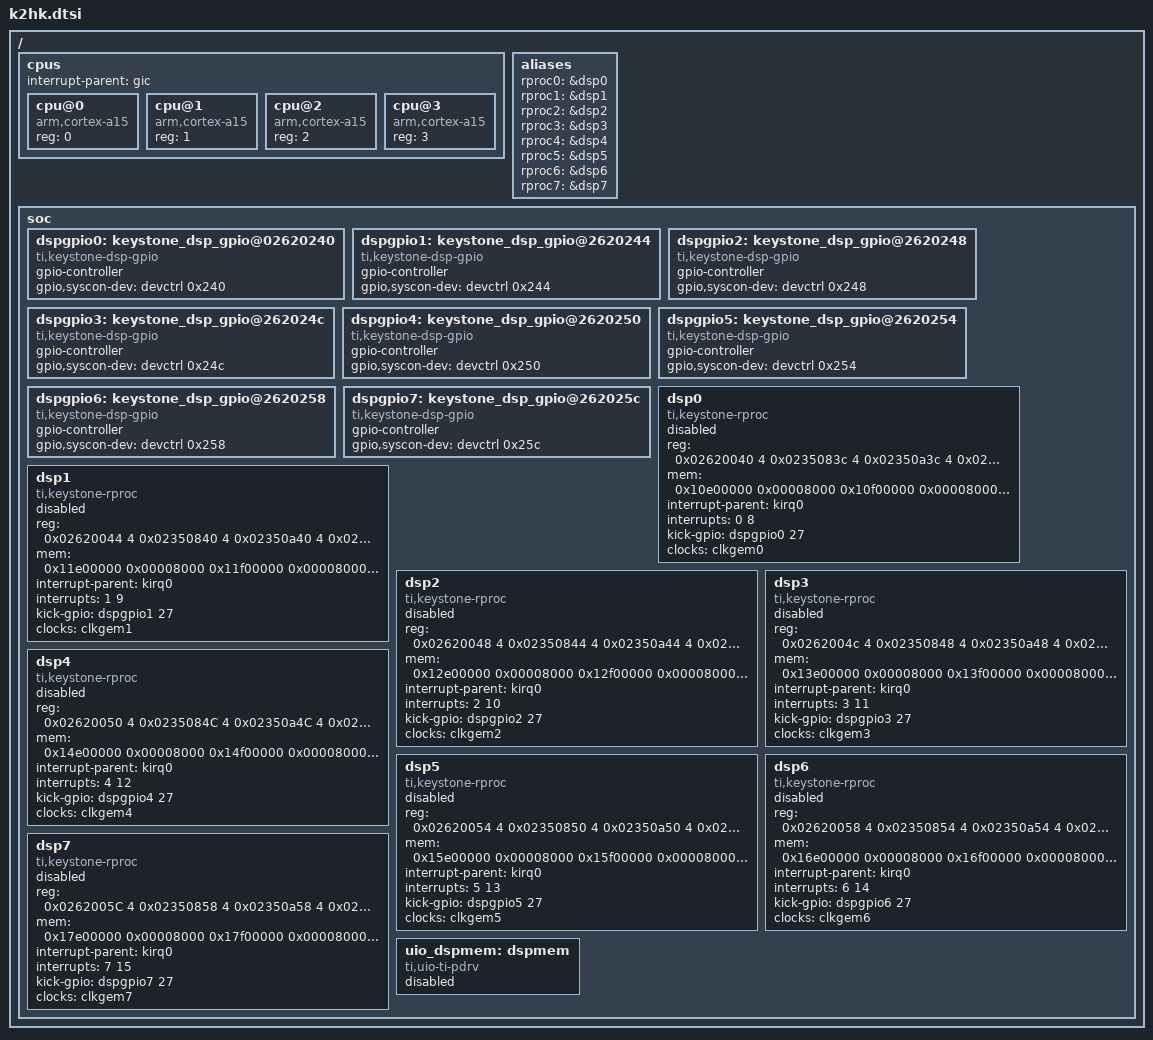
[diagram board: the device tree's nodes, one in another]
/*
 * Copyright 2013-2014 Texas Instruments, Inc.
 *
 * Keystone 2 Kepler/Hawking soc specific device tree
 *
 * This program is free software; you can redistribute it and/or modify
 * it under the terms of the GNU General Public License version 2 as
 * published by the Free Software Foundation.
 */

/ {
	cpus {
		#address-cells = <1>;
		#size-cells = <0>;

		interrupt-parent = <&gic>;

		cpu@0 {
			compatible = "arm,cortex-a15";
			device_type = "cpu";
			reg = <0>;
		};

		cpu@1 {
			compatible = "arm,cortex-a15";
			device_type = "cpu";
			reg = <1>;
		};

		cpu@2 {
			compatible = "arm,cortex-a15";
			device_type = "cpu";
			reg = <2>;
		};

		cpu@3 {
			compatible = "arm,cortex-a15";
			device_type = "cpu";
			reg = <3>;
		};
	};
	aliases {
		rproc0 = &dsp0;
		rproc1 = &dsp1;
		rproc2 = &dsp2;
		rproc3 = &dsp3;
		rproc4 = &dsp4;
		rproc5 = &dsp5;
		rproc6 = &dsp6;
		rproc7 = &dsp7;
	};
	soc {
		/include/ "k2hk-clocks.dtsi"

		dspgpio0: keystone_dsp_gpio@02620240 {
			compatible = "ti,keystone-dsp-gpio";
			gpio-controller;
			#gpio-cells = <2>;
			gpio,syscon-dev = <&devctrl 0x240>;
		};

		dspgpio1: keystone_dsp_gpio@2620244 {
			compatible = "ti,keystone-dsp-gpio";
			gpio-controller;
			#gpio-cells = <2>;
			gpio,syscon-dev = <&devctrl 0x244>;
		};

		dspgpio2: keystone_dsp_gpio@2620248 {
			compatible = "ti,keystone-dsp-gpio";
			gpio-controller;
			#gpio-cells = <2>;
			gpio,syscon-dev = <&devctrl 0x248>;
		};

		dspgpio3: keystone_dsp_gpio@262024c {
			compatible = "ti,keystone-dsp-gpio";
			gpio-controller;
			#gpio-cells = <2>;
			gpio,syscon-dev = <&devctrl 0x24c>;
		};

		dspgpio4: keystone_dsp_gpio@2620250 {
			compatible = "ti,keystone-dsp-gpio";
			gpio-controller;
			#gpio-cells = <2>;
			gpio,syscon-dev = <&devctrl 0x250>;
		};

		dspgpio5: keystone_dsp_gpio@2620254 {
			compatible = "ti,keystone-dsp-gpio";
			gpio-controller;
			#gpio-cells = <2>;
			gpio,syscon-dev = <&devctrl 0x254>;
		};

		dspgpio6: keystone_dsp_gpio@2620258 {
			compatible = "ti,keystone-dsp-gpio";
			gpio-controller;
			#gpio-cells = <2>;
			gpio,syscon-dev = <&devctrl 0x258>;
		};

		dspgpio7: keystone_dsp_gpio@262025c {
			compatible = "ti,keystone-dsp-gpio";
			gpio-controller;
			#gpio-cells = <2>;
			gpio,syscon-dev = <&devctrl 0x25c>;
		};
		dsp0: dsp0 {
			compatible = "ti,keystone-rproc";
			reg = <0x02620040 4
			       0x0235083c 4
			       0x02350a3c 4
			       0x02620240 4>;
			reg-names = "boot-address", "psc-mdstat", "psc-mdctl",
				"ipcgr";
			mem = <0x10e00000 0x00008000
			       0x10f00000 0x00008000
			       0x10800000 0x00100000>;
			interrupt-parent = <&kirq0>;
			interrupts = <0 8>;
			kick-gpio = <&dspgpio0 27 0>;
			clocks = <&clkgem0>;
			status = "disabled";
		};

		dsp1: dsp1 {
			compatible = "ti,keystone-rproc";
			reg = <0x02620044 4
			       0x02350840 4
			       0x02350a40 4
			       0x02620244 4>;
			reg-names = "boot-address", "psc-mdstat", "psc-mdctl",
				"ipcgr";
			mem = <0x11e00000 0x00008000
			       0x11f00000 0x00008000
			       0x11800000 0x00100000>;
			interrupt-parent = <&kirq0>;
			interrupts = <1 9>;
			kick-gpio = <&dspgpio1 27 0>;
			clocks = <&clkgem1>;
			status = "disabled";
		};

		dsp2: dsp2 {
			compatible = "ti,keystone-rproc";
			reg = <0x02620048 4
			       0x02350844 4
			       0x02350a44 4
			       0x02620248 4>;
			reg-names = "boot-address", "psc-mdstat", "psc-mdctl",
				"ipcgr";
			mem = <0x12e00000 0x00008000
			       0x12f00000 0x00008000
			       0x12800000 0x00100000>;
			interrupt-parent = <&kirq0>;
			interrupts = <2 10>;
			kick-gpio = <&dspgpio2 27 0>;
			clocks = <&clkgem2>;
			status = "disabled";
		};

		dsp3: dsp3 {
			compatible = "ti,keystone-rproc";
			reg = <0x0262004c 4
			       0x02350848 4
			       0x02350a48 4
			       0x0262024c 4>;
			reg-names = "boot-address", "psc-mdstat", "psc-mdctl",
				"ipcgr";
			mem = <0x13e00000 0x00008000
			       0x13f00000 0x00008000
			       0x13800000 0x00100000>;
			interrupt-parent = <&kirq0>;
			interrupts = <3 11>;
			kick-gpio = <&dspgpio3 27 0>;
			clocks = <&clkgem3>;
			status = "disabled";
		};

		dsp4: dsp4 {
			compatible = "ti,keystone-rproc";
			reg = <0x02620050 4
			       0x0235084C 4
			       0x02350a4C 4
			       0x02620250 4>;
			reg-names = "boot-address", "psc-mdstat", "psc-mdctl",
				"ipcgr";
			mem = <0x14e00000 0x00008000
			       0x14f00000 0x00008000
			       0x14800000 0x00100000>;
			interrupt-parent = <&kirq0>;
			interrupts = <4 12>;
			kick-gpio = <&dspgpio4 27 0>;
			clocks = <&clkgem4>;
			status = "disabled";
		};

		dsp5: dsp5 {
			compatible = "ti,keystone-rproc";
			reg = <0x02620054 4
			       0x02350850 4
			       0x02350a50 4
			       0x02620254 4>;
			reg-names = "boot-address", "psc-mdstat", "psc-mdctl",
				"ipcgr";
			mem = <0x15e00000 0x00008000
			       0x15f00000 0x00008000
			       0x15800000 0x00100000>;
			interrupt-parent = <&kirq0>;
			interrupts = <5 13>;
			kick-gpio = <&dspgpio5 27 0>;
			clocks = <&clkgem5>;
			status = "disabled";
		};

		dsp6: dsp6 {
			compatible = "ti,keystone-rproc";
			reg = <0x02620058 4
			       0x02350854 4
			       0x02350a54 4
			       0x02620258 4>;
			reg-names = "boot-address", "psc-mdstat", "psc-mdctl",
				"ipcgr";
			mem = <0x16e00000 0x00008000
			       0x16f00000 0x00008000
			       0x16800000 0x00100000>;
			interrupt-parent = <&kirq0>;
			interrupts = <6 14>;
			kick-gpio = <&dspgpio6 27 0>;
			clocks = <&clkgem6>;
			status = "disabled";
		};

		dsp7: dsp7 {
			compatible = "ti,keystone-rproc";
			reg = <0x0262005C 4
			       0x02350858 4
			       0x02350a58 4
			       0x0262025C 4>;
			reg-names = "boot-address", "psc-mdstat", "psc-mdctl",
				"ipcgr";
			mem = <0x17e00000 0x00008000
			       0x17f00000 0x00008000
			       0x17800000 0x00100000>;
			interrupt-parent = <&kirq0>;
			interrupts = <7 15>;
			kick-gpio = <&dspgpio7 27 0>;
			clocks = <&clkgem7>;
			status = "disabled";
		};

		uio_dspmem: dspmem {
			compatible = "ti,uio-ti-pdrv";
			status = "disabled";
		};
		/include/ "k2hk-netcp.dtsi"
	};
};
